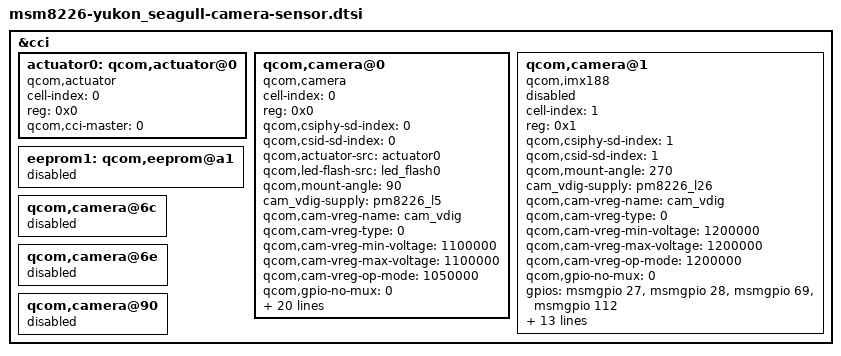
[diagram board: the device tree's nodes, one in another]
/*
 * Copyright (c) 2013, The Linux Foundation. All rights reserved.
 * Copyright(C) 2013 Foxconn International Holdings, Ltd. All rights.
 *
 * This program is free software; you can redistribute it and/or modify
 * it under the terms of the GNU General Public License version 2 and
 * only version 2 as published by the Free Software Foundation.
 *
 * This program is distributed in the hope that it will be useful,
 * but WITHOUT ANY WARRANTY; without even the implied warranty of
 * MERCHANTABILITY or FITNESS FOR A PARTICULAR PURPOSE.  See the
 * GNU General Public License for more details.
 */

&cci {
	actuator0: qcom,actuator@0 {
		cell-index = <0>;
		reg = <0x0>;
		compatible = "qcom,actuator";
		qcom,cci-master = <0>;
	};

	qcom,camera@0 {
		cell-index = <0>;
		compatible = "qcom,camera";
		reg = <0x0>;
		qcom,csiphy-sd-index = <0>;
		qcom,csid-sd-index = <0>;
		qcom,actuator-src = <&actuator0>;
		qcom,led-flash-src = <&led_flash0>;
		qcom,mount-angle = <90>;
		cam_vdig-supply = <&pm8226_l5>;
		qcom,cam-vreg-name = "cam_vdig";
		qcom,cam-vreg-type = <0>;
		qcom,cam-vreg-min-voltage = <1100000>;
		qcom,cam-vreg-max-voltage = <1100000>;
		qcom,cam-vreg-op-mode = <1050000>;
		qcom,gpio-no-mux = <0>;
		gpios = <&msmgpio 26 0>,
			<&msmgpio 36 0>,
			<&msmgpio 69 0>,
			<&msmgpio 111 0>,
			<&msmgpio 112 0>;
		qcom,gpio-reset = <1>;
		qcom,gpio-vana = <2>;
		qcom,gpio-vaf = <3>;
		qcom,gpio-vio = <4>;
		qcom,gpio-req-tbl-num = <0 1 2 3 4>;
		qcom,gpio-req-tbl-flags = <1 0 0 0 0>;
		qcom,gpio-req-tbl-label = "CAMIF_MCLK0",
			"CAM_RESET0",
			"SENSOR_GPIO_VANA",
			"SENSOR_GPIO_VAF",
			"SENSOR_GPIO_VIO";
		qcom,csi-lane-assign = <0x4320>;
		qcom,csi-lane-mask = <0x1F>;
		qcom,sensor-position = <0>;
		qcom,sensor-mode = <0>;
		qcom,sensor-type = <0>;
		qcom,cci-master = <0>;
		qcom,actuator-cam-name = <3>;
		qcom,actuator-vcm-pwd = <111>;
		qcom,actuator-vcm-enable = <1>;

		status = "ok";
		clock-names = "cam_src_clk", "cam_clk";
	};

	qcom,camera@1 {
		cell-index = <1>;
		compatible = "qcom,imx188";
		reg = <0x1>;
		qcom,csiphy-sd-index = <1>;
		qcom,csid-sd-index = <1>;
		qcom,mount-angle = <270>;
		cam_vdig-supply = <&pm8226_l26>;
		qcom,cam-vreg-name = "cam_vdig";
		qcom,cam-vreg-type = <0>;
		qcom,cam-vreg-min-voltage = <1200000>;
		qcom,cam-vreg-max-voltage = <1200000>;
		qcom,cam-vreg-op-mode = <1200000>;
		qcom,gpio-no-mux = <0>;
		gpios = <&msmgpio 27 0>,
			<&msmgpio 28 0>,
			<&msmgpio 69 0>,
			<&msmgpio 112 0>;
		qcom,gpio-reset = <1>;
		qcom,gpio-vana = <2>;
		qcom,gpio-vio = <3>;
		qcom,gpio-req-tbl-num = <0 1 2 3>;
		qcom,gpio-req-tbl-flags = <1 0 0 0>;
		qcom,gpio-req-tbl-label = "CAMIF_MCLK",
				"CAM_RESET",
				"SENSOR_GPIO_VANA",
				"SENSOR_GPIO_VIO";
		qcom,csi-lane-assign = <0x4320>;
		qcom,csi-lane-mask = <0x3>;
		qcom,sensor-position = <1>;
		qcom,sensor-mode = <1>;
		qcom,sensor-type = <0>;
		qcom,cci-master = <0>;
		status = "disabled";
	};


	eeprom1: qcom,eeprom@a1 {
		status = "disabled";
	};

	qcom,camera@6c {
		status = "disabled";
	};

	/* disable Qualcomm camera sensors */
	qcom,camera@6e {
		status = "disabled";
	};

	qcom,camera@90 {
		status = "disabled";
	};
};
